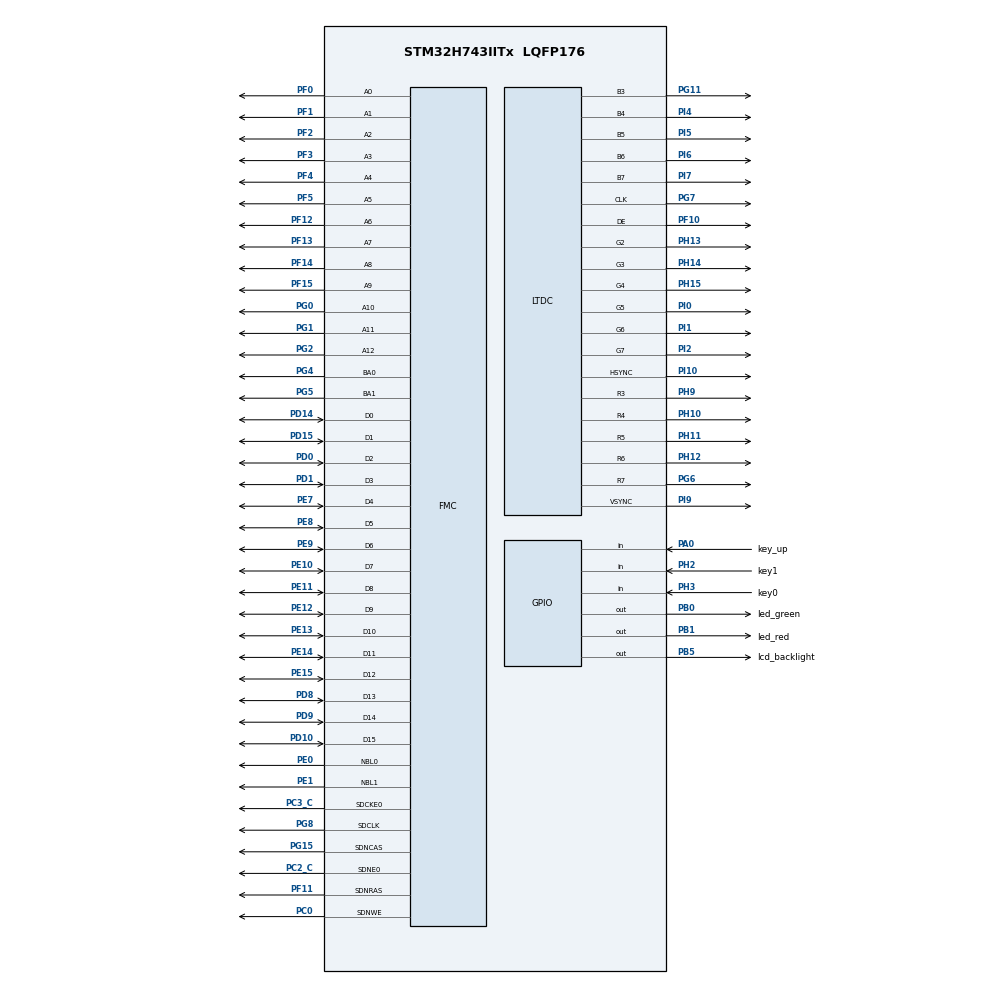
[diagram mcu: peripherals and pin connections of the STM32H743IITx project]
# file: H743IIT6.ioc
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CORTEX_M7.AccessPermission_S-Cortex_Memory_Protection_Unit_Region1_Settings_S=MPU_REGION_FULL_ACCESS
CORTEX_M7.AccessPermission_S-Cortex_Memory_Protection_Unit_Region2_Settings_S=MPU_REGION_FULL_ACCESS
CORTEX_M7.AccessPermission_Spec=MPU_REGION_FULL_ACCESS
CORTEX_M7.BaseAddress_S-Cortex_Memory_Protection_Unit_Region1_Settings_S=0x24000000
CORTEX_M7.BaseAddress_S-Cortex_Memory_Protection_Unit_Region2_Settings_S=0x60000000
CORTEX_M7.BaseAddress_Spec=0x20000000
CORTEX_M7.CPU_DCache=Enabled
CORTEX_M7.CPU_ICache=Enabled
CORTEX_M7.DisableExec_Spec=MPU_INSTRUCTION_ACCESS_ENABLE
CORTEX_M7.Enable_S-Cortex_Memory_Protection_Unit_Region1_Settings_S=MPU_REGION_ENABLE
CORTEX_M7.Enable_S-Cortex_Memory_Protection_Unit_Region2_Settings_S=MPU_REGION_ENABLE
CORTEX_M7.Enable_Spec=MPU_REGION_ENABLE
CORTEX_M7.IsBufferable_S-Cortex_Memory_Protection_Unit_Region2_Settings_S=MPU_ACCESS_BUFFERABLE
CORTEX_M7.IsBufferable_Spec=MPU_ACCESS_BUFFERABLE
CORTEX_M7.IsCacheable_S-Cortex_Memory_Protection_Unit_Region1_Settings_S=MPU_ACCESS_CACHEABLE
CORTEX_M7.IsCacheable_S-Cortex_Memory_Protection_Unit_Region2_Settings_S=MPU_ACCESS_CACHEABLE
CORTEX_M7.IsCacheable_Spec=MPU_ACCESS_CACHEABLE
CORTEX_M7.IsShareable_S-Cortex_Memory_Protection_Unit_Region1_Settings_S=MPU_ACCESS_SHAREABLE
CORTEX_M7.IsShareable_Spec=MPU_ACCESS_NOT_SHAREABLE
CORTEX_M7.Size_S-Cortex_Memory_Protection_Unit_Region1_Settings_S=MPU_REGION_SIZE_512KB
CORTEX_M7.Size_S-Cortex_Memory_Protection_Unit_Region2_Settings_S=MPU_REGION_SIZE_32MB
CORTEX_M7.Size_Spec=MPU_REGION_SIZE_128KB
CORTEX_M7.SubRegionDisable_Spec=0x0
CORTEX_M7.default_mode_Activation=1
DMA2D.ColorMode=DMA2D_OUTPUT_RGB565
FMC.BankMapConfig=FMC_SWAPBMAP_SDRAM_SRAM
FMC.CASLatency1=FMC_SDRAM_CAS_LATENCY_2
FMC.ColumnBitsNumber1=FMC_SDRAM_COLUMN_BITS_NUM_9
FMC.ExitSelfRefreshDelay1=8
FMC.LoadToActiveDelay1=2
FMC.RCDDelay1=2
FMC.RPDelay1=2
FMC.ReadBurst1=FMC_SDRAM_RBURST_ENABLE
FMC.RowCycleDelay1=6
FMC.SDClockPeriod1=FMC_SDRAM_CLOCK_PERIOD_2
FMC.SelfRefreshTime1=6
FMC.WriteProtection1=FMC_SDRAM_WRITE_PROTECTION_DISABLE
FMC.WriteRecoveryTime1=4
LTDC.ActiveH=480
LTDC.ActiveW=800
LTDC.Alpha_L0=255
LTDC.Alpha_L1=255
LTDC.Blue_L0=0
LTDC.FBStartAdress_L0=0x60000000
LTDC.HBP=0
LTDC.HFP=210
LTDC.HSync=1
LTDC.ImageHeight_L0=480
LTDC.ImageWidth_L0=800
LTDC.Layers=0
LTDC.PixelFormat_L0=LTDC_PIXEL_FORMAT_RGB565
LTDC.Red=0
LTDC.Red_L1=255
LTDC.VBP=0
LTDC.VFP=22
LTDC.VSync=1
LTDC.WindowX0_L1=100
LTDC.WindowX1_L0=800
LTDC.WindowX1_L1=300
LTDC.WindowY0_L1=100
LTDC.WindowY1_L0=480
LTDC.WindowY1_L1=300
Mcu.Family=STM32H7
Mcu.Name=STM32H743IITx
Mcu.Package=LQFP176
NVIC.DMA2D_IRQn=true\:8\:0\:true\:false\:true\:true\:true\:true
NVIC.LTDC_IRQn=true\:9\:0\:true\:false\:true\:true\:true\:true
NVIC.PriorityGroup=NVIC_PRIORITYGROUP_4
PA0.GPIO_Label=key_up
PA0.GPIO_PuPd=GPIO_PULLDOWN
PA0.Signal=GPIO_Input
PA13\ (JTMS/SWDIO).Mode=Serial_Wire
PA13\ (JTMS/SWDIO).Signal=DEBUG_JTMS-SWDIO
PA14\ (JTCK/SWCLK).Mode=Serial_Wire
PA14\ (JTCK/SWCLK).Signal=DEBUG_JTCK-SWCLK
PB0.GPIO_Label=led_green
PB0.GPIO_PuPd=GPIO_PULLUP
PB0.GPIO_Speed=GPIO_SPEED_FREQ_VERY_HIGH
PB0.PinState=GPIO_PIN_SET
PB0.Signal=GPIO_Output
PB1.GPIO_Label=led_red
PB1.GPIO_PuPd=GPIO_PULLUP
PB1.GPIO_Speed=GPIO_SPEED_FREQ_VERY_HIGH
PB1.PinState=GPIO_PIN_SET
PB1.Signal=GPIO_Output
PB5.GPIO_Label=lcd_backlight
PB5.GPIO_PuPd=GPIO_PULLUP
PB5.GPIO_Speed=GPIO_SPEED_FREQ_VERY_HIGH
PB5.Signal=GPIO_Output
PC0.GPIO_PuPd=GPIO_PULLUP
PC0.Signal=FMC_SDNWE
PC2_C.Mode=SdramChipSelect1_1
PC2_C.Signal=FMC_SDNE0
PC3_C.Mode=SdramChipSelect1_1
PC3_C.Signal=FMC_SDCKE0
PD0.GPIO_PuPd=GPIO_PULLUP
PD0.Signal=FMC_D2_DA2
PD1.GPIO_PuPd=GPIO_PULLUP
PD1.Signal=FMC_D3_DA3
PD10.GPIO_PuPd=GPIO_PULLUP
PD10.Signal=FMC_D15_DA15
PD14.GPIO_PuPd=GPIO_PULLUP
PD14.Signal=FMC_D0_DA0
PD15.GPIO_PuPd=GPIO_PULLUP
PD15.Signal=FMC_D1_DA1
PD8.GPIO_PuPd=GPIO_PULLUP
PD8.Signal=FMC_D13_DA13
PD9.GPIO_PuPd=GPIO_PULLUP
PD9.Signal=FMC_D14_DA14
PE0.GPIO_PuPd=GPIO_PULLUP
PE0.Signal=FMC_NBL0
PE1.GPIO_PuPd=GPIO_PULLUP
PE1.Signal=FMC_NBL1
PE10.GPIO_PuPd=GPIO_PULLUP
PE10.Signal=FMC_D7_DA7
PE11.GPIO_PuPd=GPIO_PULLUP
PE11.Signal=FMC_D8_DA8
PE12.GPIO_PuPd=GPIO_PULLUP
PE12.Signal=FMC_D9_DA9
PE13.GPIO_PuPd=GPIO_PULLUP
PE13.Signal=FMC_D10_DA10
PE14.GPIO_PuPd=GPIO_PULLUP
PE14.Signal=FMC_D11_DA11
PE15.GPIO_PuPd=GPIO_PULLUP
PE15.Signal=FMC_D12_DA12
PE7.GPIO_PuPd=GPIO_PULLUP
PE7.Signal=FMC_D4_DA4
PE8.GPIO_PuPd=GPIO_PULLUP
PE8.Signal=FMC_D5_DA5
PE9.GPIO_PuPd=GPIO_PULLUP
PE9.Signal=FMC_D6_DA6
PF0.GPIO_PuPd=GPIO_PULLUP
PF0.Signal=FMC_A0
PF1.GPIO_PuPd=GPIO_PULLUP
PF1.Signal=FMC_A1
PF10.GPIO_Speed=GPIO_SPEED_FREQ_VERY_HIGH
PF10.Mode=RGB565
PF10.Signal=LTDC_DE
PF11.GPIO_PuPd=GPIO_PULLUP
PF11.Signal=FMC_SDNRAS
PF12.GPIO_PuPd=GPIO_PULLUP
PF12.Signal=FMC_A6
PF13.GPIO_PuPd=GPIO_PULLUP
PF13.Signal=FMC_A7
PF14.GPIO_PuPd=GPIO_PULLUP
PF14.Signal=FMC_A8
PF15.GPIO_PuPd=GPIO_PULLUP
PF15.Signal=FMC_A9
PF2.GPIO_PuPd=GPIO_PULLUP
PF2.Signal=FMC_A2
PF3.GPIO_PuPd=GPIO_PULLUP
PF3.Signal=FMC_A3
PF4.GPIO_PuPd=GPIO_PULLUP
PF4.Signal=FMC_A4
PF5.GPIO_PuPd=GPIO_PULLUP
PF5.Signal=FMC_A5
PG0.GPIO_PuPd=GPIO_PULLUP
PG0.Signal=FMC_A10
PG1.GPIO_PuPd=GPIO_PULLUP
PG1.Signal=FMC_A11
PG11.GPIO_Speed=GPIO_SPEED_FREQ_VERY_HIGH
PG11.Mode=RGB565
PG11.Signal=LTDC_B3
PG15.GPIO_PuPd=GPIO_PULLUP
PG15.Signal=FMC_SDNCAS
PG2.GPIO_PuPd=GPIO_PULLUP
PG2.Signal=FMC_A12
PG4.GPIO_PuPd=GPIO_PULLUP
PG4.Signal=FMC_A14_BA0
PG5.GPIO_PuPd=GPIO_PULLUP
PG5.Signal=FMC_A15_BA1
PG6.GPIO_Speed=GPIO_SPEED_FREQ_VERY_HIGH
PG6.Mode=RGB565
PG6.Signal=LTDC_R7
PG7.GPIO_Speed=GPIO_SPEED_FREQ_VERY_HIGH
PG7.Mode=RGB565
PG7.Signal=LTDC_CLK
PG8.GPIO_PuPd=GPIO_PULLUP
PG8.Signal=FMC_SDCLK
PH0-OSC_IN\ (PH0).Mode=HSE-External-Oscillator
PH0-OSC_IN\ (PH0).Signal=RCC_OSC_IN
PH1-OSC_OUT\ (PH1).Mode=HSE-External-Oscillator
PH1-OSC_OUT\ (PH1).Signal=RCC_OSC_OUT
PH10.GPIO_Speed=GPIO_SPEED_FREQ_VERY_HIGH
PH10.Mode=RGB565
PH10.Signal=LTDC_R4
PH11.GPIO_Speed=GPIO_SPEED_FREQ_VERY_HIGH
PH11.Mode=RGB565
PH11.Signal=LTDC_R5
PH12.GPIO_Speed=GPIO_SPEED_FREQ_VERY_HIGH
PH12.Mode=RGB565
PH12.Signal=LTDC_R6
PH13.GPIO_Speed=GPIO_SPEED_FREQ_VERY_HIGH
PH13.Mode=RGB565
PH13.Signal=LTDC_G2
PH14.GPIO_Speed=GPIO_SPEED_FREQ_VERY_HIGH
PH14.Mode=RGB565
PH14.Signal=LTDC_G3
PH15.GPIO_Speed=GPIO_SPEED_FREQ_VERY_HIGH
PH15.Mode=RGB565
PH15.Signal=LTDC_G4
PH2.GPIO_Label=key1
PH2.GPIO_PuPd=GPIO_PULLUP
PH2.Signal=GPIO_Input
PH3.GPIO_Label=key0
PH3.GPIO_PuPd=GPIO_PULLUP
PH3.Signal=GPIO_Input
PH9.GPIO_Speed=GPIO_SPEED_FREQ_VERY_HIGH
PH9.Mode=RGB565
PH9.Signal=LTDC_R3
PI0.GPIO_Speed=GPIO_SPEED_FREQ_VERY_HIGH
PI0.Mode=RGB565
PI0.Signal=LTDC_G5
PI1.GPIO_Speed=GPIO_SPEED_FREQ_VERY_HIGH
PI1.Mode=RGB565
PI1.Signal=LTDC_G6
PI10.GPIO_Speed=GPIO_SPEED_FREQ_VERY_HIGH
PI10.Mode=RGB565
PI10.Signal=LTDC_HSYNC
PI2.GPIO_Speed=GPIO_SPEED_FREQ_VERY_HIGH
PI2.Mode=RGB565
PI2.Signal=LTDC_G7
PI4.GPIO_Speed=GPIO_SPEED_FREQ_VERY_HIGH
PI4.Mode=RGB565
PI4.Signal=LTDC_B4
PI5.GPIO_Speed=GPIO_SPEED_FREQ_VERY_HIGH
PI5.Mode=RGB565
PI5.Signal=LTDC_B5
PI6.GPIO_Speed=GPIO_SPEED_FREQ_VERY_HIGH
PI6.Mode=RGB565
PI6.Signal=LTDC_B6
PI7.GPIO_Speed=GPIO_SPEED_FREQ_VERY_HIGH
PI7.Mode=RGB565
PI7.Signal=LTDC_B7
PI9.GPIO_Speed=GPIO_SPEED_FREQ_VERY_HIGH
PI9.Mode=RGB565
PI9.Signal=LTDC_VSYNC
ProjectManager.HeapSize=0x200
ProjectManager.StackSize=0x400
ProjectManager.TargetToolchain=MDK-ARM V5.32
RCC.ADCFreq_Value=50390625
RCC.APB1Freq_Value=120000000
RCC.APB2Freq_Value=120000000
RCC.APB3Freq_Value=120000000
RCC.APB4Freq_Value=120000000
RCC.CortexFreq_Value=480000000
RCC.D1PPRE=RCC_APB3_DIV2
RCC.D2PPRE1=RCC_APB1_DIV2
RCC.D2PPRE2=RCC_APB2_DIV2
RCC.D3PPRE=RCC_APB4_DIV2
RCC.DIVM1=5
RCC.DIVM3=2
RCC.DIVN1=192
RCC.DIVN3=18
RCC.DIVR3=9
RCC.HCLKFreq_Value=240000000
RCC.HPRE=RCC_HCLK_DIV2
RCC.PLL2FRACN=0
RCC.PLL3FRACN=0
RCC.PLLFRACN=0
RCC.PLLSourceVirtual=RCC_PLLSOURCE_HSE
RCC.SYSCLKFreq_VALUE=480000000
RCC.SYSCLKSource=RCC_SYSCLKSOURCE_PLLCLK
RCC.USBFreq_Value=480000000
SH.FMC_A0.0=FMC_A0,13b-sda1
SH.FMC_A1.0=FMC_A1,13b-sda1
SH.FMC_A10.0=FMC_A10,13b-sda1
SH.FMC_A11.0=FMC_A11,13b-sda1
SH.FMC_A12.0=FMC_A12,13b-sda1
SH.FMC_A14_BA0.0=FMC_BA0,FourSdramBanks1
SH.FMC_A15_BA1.0=FMC_BA1,FourSdramBanks1
SH.FMC_A2.0=FMC_A2,13b-sda1
SH.FMC_A3.0=FMC_A3,13b-sda1
SH.FMC_A4.0=FMC_A4,13b-sda1
SH.FMC_A5.0=FMC_A5,13b-sda1
SH.FMC_A6.0=FMC_A6,13b-sda1
SH.FMC_A7.0=FMC_A7,13b-sda1
SH.FMC_A8.0=FMC_A8,13b-sda1
SH.FMC_A9.0=FMC_A9,13b-sda1
SH.FMC_D0_DA0.0=FMC_D0,sd-16b-d1
SH.FMC_D10_DA10.0=FMC_D10,sd-16b-d1
SH.FMC_D11_DA11.0=FMC_D11,sd-16b-d1
SH.FMC_D12_DA12.0=FMC_D12,sd-16b-d1
SH.FMC_D13_DA13.0=FMC_D13,sd-16b-d1
SH.FMC_D14_DA14.0=FMC_D14,sd-16b-d1
SH.FMC_D15_DA15.0=FMC_D15,sd-16b-d1
SH.FMC_D1_DA1.0=FMC_D1,sd-16b-d1
SH.FMC_D2_DA2.0=FMC_D2,sd-16b-d1
SH.FMC_D3_DA3.0=FMC_D3,sd-16b-d1
SH.FMC_D4_DA4.0=FMC_D4,sd-16b-d1
SH.FMC_D5_DA5.0=FMC_D5,sd-16b-d1
SH.FMC_D6_DA6.0=FMC_D6,sd-16b-d1
SH.FMC_D7_DA7.0=FMC_D7,sd-16b-d1
SH.FMC_D8_DA8.0=FMC_D8,sd-16b-d1
SH.FMC_D9_DA9.0=FMC_D9,sd-16b-d1
SH.FMC_NBL0.0=FMC_NBL0,Sd2ByteEnable1
SH.FMC_NBL1.0=FMC_NBL1,Sd2ByteEnable1
SH.FMC_SDCLK.0=FMC_SDCLK,13b-sda1
SH.FMC_SDNCAS.0=FMC_SDNCAS,13b-sda1
SH.FMC_SDNRAS.0=FMC_SDNRAS,13b-sda1
SH.FMC_SDNWE.0=FMC_SDNWE,13b-sda1
VP_DMA2D_VS_DMA2D.Mode=DMA2D_Activate
VP_MEMORYMAP_VS_MEMORYMAP.Mode=CurAppReg
board=custom

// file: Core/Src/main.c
/* USER CODE BEGIN Header */
/**
  ******************************************************************************
  * @file           : main.c
  * @brief          : Main program body
  ******************************************************************************
  * @attention
  *
  * Copyright (c) 2026 STMicroelectronics.
  * All rights reserved.
  *
  * This software is licensed under terms that can be found in the LICENSE file
  * in the root directory of this software component.
  * If no LICENSE file comes with this software, it is provided AS-IS.
  *
  ******************************************************************************
  */
/* USER CODE END Header */
#include "main.h"
#include "dma2d.h"
#include "ltdc.h"
#include "gpio.h"
#include "fmc.h"

/* USER CODE BEGIN Includes */
#include "system.h"
/* USER CODE END Includes */

void SystemClock_Config(void);
static void MPU_Config(void);

/* USER CODE BEGIN 0 */
// 帧缓冲 0 和帧缓冲 1，各 768KB
uint16_t frame_buf_0[480 * 800] __attribute__((at(0x60000000)));
uint16_t frame_buf_1[480 * 800] __attribute__((at(0x600C0000)));  // 偏移 0xC0000

// 记录当前“后台”缓冲（用于绘制）
static uint16_t *back_buf = frame_buf_0;
static uint16_t *front_buf = frame_buf_1;  // LTDC 当前正在显示的

static void dma2d_fill(uint16_t color)
{
	while (DMA2D->CR & DMA2D_CR_START);
	DMA2D->CR     = DMA2D_R2M;
	DMA2D->OPFCCR = DMA2D_OUTPUT_RGB565;
	DMA2D->OCOLR  = color;
	DMA2D->OMAR   = (uint32_t)back_buf;   // 写后台
	DMA2D->OOR    = 0;
	DMA2D->NLR    = (480 << 16) | 800;    // 480 列，800 行
	DMA2D->CR    |= DMA2D_CR_START;
//	while (DMA2D->CR & DMA2D_CR_START);   // 等填充完成
}

static void swap_buffers(void)
{
	// 确保 DMA2D 已写完后台缓冲
	while (DMA2D->CR & DMA2D_CR_START);

	// 把新地址写入 LTDC 影子寄存器（不立即生效）
	HAL_LTDC_SetAddress_NoReload(&hltdc, (uint32_t)back_buf, 0);

	// 在下一个垂直消隐期重载，安全切换
	HAL_LTDC_Reload(&hltdc, LTDC_RELOAD_VERTICAL_BLANKING);

	// 交换前后台指针
	uint16_t *tmp = back_buf;
	back_buf = front_buf;
	front_buf = tmp;
}
/* USER CODE END 0 */

int main(void)
{

  /* MPU Configuration--------------------------------------------------------*/
  MPU_Config();

  /* Enable the CPU Cache */

  /* Enable I-Cache---------------------------------------------------------*/
  SCB_EnableICache();

  /* Enable D-Cache---------------------------------------------------------*/
  SCB_EnableDCache();

  /* MCU Configuration--------------------------------------------------------*/

  /* Reset of all peripherals, Initializes the Flash interface and the Systick. */
  HAL_Init();

  /* USER CODE BEGIN Init */
	// 开启CPU一级缓存
	Cache_Enable();
  /* USER CODE END Init */

  /* Configure the system clock */
  SystemClock_Config();

  /* Initialize all configured peripherals */
  MX_GPIO_Init();
  MX_FMC_Init();
  MX_LTDC_Init();
  MX_DMA2D_Init();
  /* USER CODE BEGIN 2 */
	// 段收集自动初始化
	auto_initcalls();

	// 开启背光
	HAL_GPIO_WritePin(lcd_backlight_GPIO_Port, lcd_backlight_Pin, GPIO_PIN_SET);
  /* USER CODE END 2 */

  /* Infinite loop */
  while (1)
  {

    /* USER CODE BEGIN 3 */
//		uint32_t tick = HAL_GetTick();
//
//		// led状态机
//		LED_FSM_Run(led_green_fsm,	tick);
//		LED_FSM_Run(led_red_fsm,		tick);
//
//		// key状态机
//		app_key_fsm_run(tick);
//
//		static uint16_t color = 0;

		dma2d_fill(0xF800);
		swap_buffers();

//		dma2d_fill(0x07E0);
//		swap_buffers();

		dma2d_fill(0x001F);
		swap_buffers();
  }
  /* USER CODE END 3 */
}

void SystemClock_Config(void)
{
  RCC_OscInitTypeDef RCC_OscInitStruct = {0};
  RCC_ClkInitTypeDef RCC_ClkInitStruct = {0};

  /** Supply configuration update enable
  */
  HAL_PWREx_ConfigSupply(PWR_LDO_SUPPLY);

  /** Configure the main internal regulator output voltage
  */
  __HAL_PWR_VOLTAGESCALING_CONFIG(PWR_REGULATOR_VOLTAGE_SCALE0);

  while(!__HAL_PWR_GET_FLAG(PWR_FLAG_VOSRDY)) {}

  /** Initializes the RCC Oscillators according to the specified parameters
  * in the RCC_OscInitTypeDef structure.
  */
  RCC_OscInitStruct.OscillatorType = RCC_OSCILLATORTYPE_HSE;
  RCC_OscInitStruct.HSEState = RCC_HSE_ON;
  RCC_OscInitStruct.PLL.PLLState = RCC_PLL_ON;
  RCC_OscInitStruct.PLL.PLLSource = RCC_PLLSOURCE_HSE;
  RCC_OscInitStruct.PLL.PLLM = 5;
  RCC_OscInitStruct.PLL.PLLN = 192;
  RCC_OscInitStruct.PLL.PLLP = 2;
  RCC_OscInitStruct.PLL.PLLQ = 2;
  RCC_OscInitStruct.PLL.PLLR = 2;
  RCC_OscInitStruct.PLL.PLLRGE = RCC_PLL1VCIRANGE_2;
  RCC_OscInitStruct.PLL.PLLVCOSEL = RCC_PLL1VCOWIDE;
  RCC_OscInitStruct.PLL.PLLFRACN = 0;
  if (HAL_RCC_OscConfig(&RCC_OscInitStruct) != HAL_OK)
  {
    Error_Handler();
  }

  /** Initializes the CPU, AHB and APB buses clocks
  */
  RCC_ClkInitStruct.ClockType = RCC_CLOCKTYPE_HCLK|RCC_CLOCKTYPE_SYSCLK
                              |RCC_CLOCKTYPE_PCLK1|RCC_CLOCKTYPE_PCLK2
                              |RCC_CLOCKTYPE_D3PCLK1|RCC_CLOCKTYPE_D1PCLK1;
  RCC_ClkInitStruct.SYSCLKSource = RCC_SYSCLKSOURCE_PLLCLK;
  RCC_ClkInitStruct.SYSCLKDivider = RCC_SYSCLK_DIV1;
  RCC_ClkInitStruct.AHBCLKDivider = RCC_HCLK_DIV2;
  RCC_ClkInitStruct.APB3CLKDivider = RCC_APB3_DIV2;
  RCC_ClkInitStruct.APB1CLKDivider = RCC_APB1_DIV2;
  RCC_ClkInitStruct.APB2CLKDivider = RCC_APB2_DIV2;
  RCC_ClkInitStruct.APB4CLKDivider = RCC_APB4_DIV2;

  if (HAL_RCC_ClockConfig(&RCC_ClkInitStruct, FLASH_LATENCY_4) != HAL_OK)
  {
    Error_Handler();
  }
}

 /* MPU Configuration */

void MPU_Config(void)
{
  MPU_Region_InitTypeDef MPU_InitStruct = {0};

  /* Disables the MPU */
  HAL_MPU_Disable();

  /** Initializes and configures the Region and the memory to be protected
  */
  MPU_InitStruct.Enable = MPU_REGION_ENABLE;
  MPU_InitStruct.Number = MPU_REGION_NUMBER0;
  MPU_InitStruct.BaseAddress = 0x20000000;
  MPU_InitStruct.Size = MPU_REGION_SIZE_128KB;
  MPU_InitStruct.SubRegionDisable = 0x0;
  MPU_InitStruct.TypeExtField = MPU_TEX_LEVEL0;
  MPU_InitStruct.AccessPermission = MPU_REGION_FULL_ACCESS;
  MPU_InitStruct.DisableExec = MPU_INSTRUCTION_ACCESS_ENABLE;
  MPU_InitStruct.IsShareable = MPU_ACCESS_NOT_SHAREABLE;
  MPU_InitStruct.IsCacheable = MPU_ACCESS_CACHEABLE;
  MPU_InitStruct.IsBufferable = MPU_ACCESS_BUFFERABLE;

  HAL_MPU_ConfigRegion(&MPU_InitStruct);

  /** Initializes and configures the Region and the memory to be protected
  */
  MPU_InitStruct.Number = MPU_REGION_NUMBER1;
  MPU_InitStruct.BaseAddress = 0x24000000;
  MPU_InitStruct.Size = MPU_REGION_SIZE_512KB;
  MPU_InitStruct.IsShareable = MPU_ACCESS_SHAREABLE;
  MPU_InitStruct.IsBufferable = MPU_ACCESS_NOT_BUFFERABLE;

  HAL_MPU_ConfigRegion(&MPU_InitStruct);

  /** Initializes and configures the Region and the memory to be protected
  */
  MPU_InitStruct.Number = MPU_REGION_NUMBER2;
  MPU_InitStruct.BaseAddress = 0x60000000;
  MPU_InitStruct.Size = MPU_REGION_SIZE_32MB;
  MPU_InitStruct.IsShareable = MPU_ACCESS_NOT_SHAREABLE;
  MPU_InitStruct.IsBufferable = MPU_ACCESS_BUFFERABLE;

  HAL_MPU_ConfigRegion(&MPU_InitStruct);
  /* Enables the MPU */
  HAL_MPU_Enable(MPU_PRIVILEGED_DEFAULT);

}

void Error_Handler(void)
{
  __disable_irq();
  while (1)
  {
  }
}
